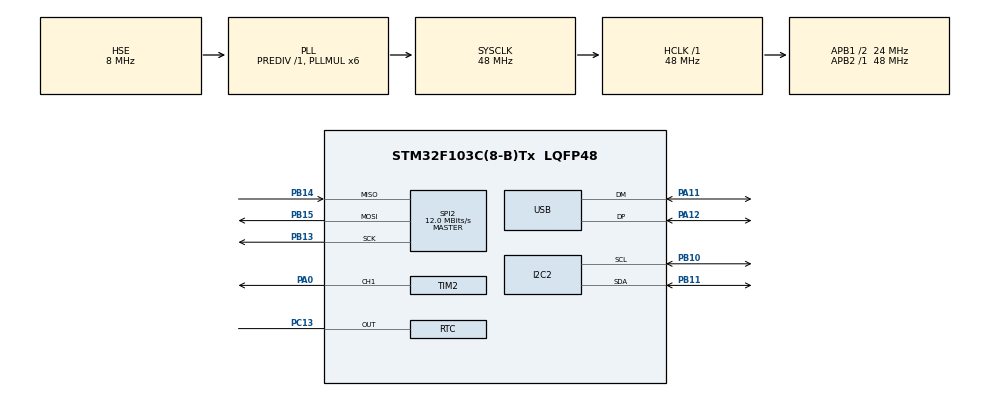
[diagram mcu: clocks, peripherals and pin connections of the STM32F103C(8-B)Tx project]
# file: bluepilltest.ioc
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Mcu.Family=STM32F1
Mcu.Name=STM32F103C(8-B)Tx
Mcu.Package=LQFP48
NVIC.PriorityGroup=NVIC_PRIORITYGROUP_4
NVIC.USB_LP_CAN1_RX0_IRQn=true\:0\:0\:false\:false\:true\:false\:true\:true
PA0-WKUP.Signal=S_TIM2_CH1_ETR
PA11.Mode=Device
PA11.Signal=USB_DM
PA12.Mode=Device
PA12.Signal=USB_DP
PB10.Mode=I2C
PB10.Signal=I2C2_SCL
PB11.Mode=I2C
PB11.Signal=I2C2_SDA
PB13.Mode=Full_Duplex_Master
PB13.Signal=SPI2_SCK
PB14.Mode=Full_Duplex_Master
PB14.Signal=SPI2_MISO
PB15.Mode=Full_Duplex_Master
PB15.Signal=SPI2_MOSI
PC13-TAMPER-RTC.Mode=RTC OUT
PC13-TAMPER-RTC.Signal=RTC_OUT
PD0-OSC_IN.Mode=HSE-External-Oscillator
PD0-OSC_IN.Signal=RCC_OSC_IN
PD1-OSC_OUT.Mode=HSE-External-Oscillator
PD1-OSC_OUT.Signal=RCC_OSC_OUT
ProjectManager.HeapSize=0x200
ProjectManager.StackSize=0x400
ProjectManager.TargetToolchain=Makefile
RCC.AHBFreq_Value=48000000
RCC.APB1CLKDivider=RCC_HCLK_DIV2
RCC.APB1Freq_Value=24000000
RCC.APB1TimFreq_Value=48000000
RCC.APB2Freq_Value=48000000
RCC.APB2TimFreq_Value=48000000
RCC.HCLKFreq_Value=48000000
RCC.PLLMUL=RCC_PLL_MUL6
RCC.SYSCLKFreq_VALUE=48000000
RCC.SYSCLKSource=RCC_SYSCLKSOURCE_PLLCLK
RCC.USBFreq_Value=48000000
SH.S_TIM2_CH1_ETR.0=TIM2_CH1,PWM Generation1 CH1
SPI2.CalculateBaudRate=12.0 MBits/s
SPI2.Direction=SPI_DIRECTION_2LINES
SPI2.Mode=SPI_MODE_MASTER
SPI2.VirtualType=VM_MASTER
TIM2.Channel-PWM\ Generation1\ CH1=TIM_CHANNEL_1
USB_DEVICE.CLASS_NAME_FS=CDC
USB_DEVICE.VirtualMode=Cdc
USB_DEVICE.VirtualModeFS=Cdc_FS
VP_FATFS_VS_Generic.Mode=User_defined
VP_RTC_VS_RTC_Activate.Mode=RTC_Enabled
VP_RTC_VS_RTC_Calendar.Mode=RTC_Calendar
VP_SYS_VS_ND.Mode=No_Debug
VP_TIM2_VS_ClockSourceINT.Mode=Internal
VP_USB_DEVICE_VS_USB_DEVICE_CDC_FS.Mode=CDC_FS
board=custom

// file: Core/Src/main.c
/* USER CODE BEGIN Header */
/**
 ******************************************************************************
 * @file           : main.c
 * @brief          : Main program body
 ******************************************************************************
 * @attention
 *
 * Copyright (c) 2023 STMicroelectronics.
 * All rights reserved.
 *
 * This software is licensed under terms that can be found in the LICENSE file
 * in the root directory of this software component.
 * If no LICENSE file comes with this software, it is provided AS-IS.
 *
 ******************************************************************************
 */
/* USER CODE END Header */
#include "main.h"
#include "fatfs.h"
#include "usb_device.h"
#include "tm_stm32_usb_device.h"
#include "tm_stm32_usb_device_cdc.h"
/* USER CODE BEGIN Includes */
#include <stdbool.h>
/* USER CODE END Includes */

I2C_HandleTypeDef hi2c2;

RTC_HandleTypeDef hrtc;

SPI_HandleTypeDef hspi2;

TIM_HandleTypeDef htim2;

/* USER CODE BEGIN PV */
uint8_t const CMD8 = 0X14;
uint8_t rxBuffer;
/* USER CODE END PV */

void SystemClock_Config(void);
static void MX_GPIO_Init(void);
static void MX_RTC_Init(void);
static void MX_TIM2_Init(void);
static void MX_SPI2_Init(void);
static void MX_I2C2_Init(void);
/* USER CODE BEGIN PFP */
void SendCmdToCard();
/* USER CODE END PFP */

/* USER CODE BEGIN 0 */
void SendCmdToCard(){

  HAL_SPI_Transmit(&hspi2,CMD8,sizeof(CMD8),HAL_MAX_DELAY);

  HAL_SPI_Receive(&hspi2, rxBuffer, sizeof(rxBuffer), HAL_MAX_DELAY);
}
/* USER CODE END 0 */

int main(void)
{

  /* MCU Configuration--------------------------------------------------------*/

  /* Reset of all peripherals, Initializes the Flash interface and the Systick. */
  HAL_Init();

  /* Configure the system clock */
  SystemClock_Config();

  /* Initialize all configured peripherals */
  MX_GPIO_Init();
  MX_RTC_Init();
  MX_TIM2_Init();
  MX_SPI2_Init();
  MX_USB_DEVICE_Init();
  MX_FATFS_Init();
  MX_I2C2_Init();

  /* Infinite loop */
   while (1)
  {

  }
}

void SystemClock_Config(void)
{
  RCC_OscInitTypeDef RCC_OscInitStruct = {0};
  RCC_ClkInitTypeDef RCC_ClkInitStruct = {0};
  RCC_PeriphCLKInitTypeDef PeriphClkInit = {0};

  /** Initializes the RCC Oscillators according to the specified parameters
  * in the RCC_OscInitTypeDef structure.
  */
  RCC_OscInitStruct.OscillatorType = RCC_OSCILLATORTYPE_LSI|RCC_OSCILLATORTYPE_HSE;
  RCC_OscInitStruct.HSEState = RCC_HSE_ON;
  RCC_OscInitStruct.HSEPredivValue = RCC_HSE_PREDIV_DIV1;
  RCC_OscInitStruct.HSIState = RCC_HSI_ON;
  RCC_OscInitStruct.LSIState = RCC_LSI_ON;
  RCC_OscInitStruct.PLL.PLLState = RCC_PLL_ON;
  RCC_OscInitStruct.PLL.PLLSource = RCC_PLLSOURCE_HSE;
  RCC_OscInitStruct.PLL.PLLMUL = RCC_PLL_MUL6;
  if (HAL_RCC_OscConfig(&RCC_OscInitStruct) != HAL_OK)
  {
    Error_Handler();
  }

  /** Initializes the CPU, AHB and APB buses clocks
  */
  RCC_ClkInitStruct.ClockType = RCC_CLOCKTYPE_HCLK|RCC_CLOCKTYPE_SYSCLK
                              |RCC_CLOCKTYPE_PCLK1|RCC_CLOCKTYPE_PCLK2;
  RCC_ClkInitStruct.SYSCLKSource = RCC_SYSCLKSOURCE_PLLCLK;
  RCC_ClkInitStruct.AHBCLKDivider = RCC_SYSCLK_DIV1;
  RCC_ClkInitStruct.APB1CLKDivider = RCC_HCLK_DIV2;
  RCC_ClkInitStruct.APB2CLKDivider = RCC_HCLK_DIV1;

  if (HAL_RCC_ClockConfig(&RCC_ClkInitStruct, FLASH_LATENCY_1) != HAL_OK)
  {
    Error_Handler();
  }
  PeriphClkInit.PeriphClockSelection = RCC_PERIPHCLK_RTC|RCC_PERIPHCLK_USB;
  PeriphClkInit.RTCClockSelection = RCC_RTCCLKSOURCE_LSI;
  PeriphClkInit.UsbClockSelection = RCC_USBCLKSOURCE_PLL;
  if (HAL_RCCEx_PeriphCLKConfig(&PeriphClkInit) != HAL_OK)
  {
    Error_Handler();
  }
}

static void MX_I2C2_Init(void)
{

  hi2c2.Instance = I2C2;
  hi2c2.Init.ClockSpeed = 100000;
  hi2c2.Init.DutyCycle = I2C_DUTYCYCLE_2;
  hi2c2.Init.OwnAddress1 = 0;
  hi2c2.Init.AddressingMode = I2C_ADDRESSINGMODE_7BIT;
  hi2c2.Init.DualAddressMode = I2C_DUALADDRESS_DISABLE;
  hi2c2.Init.OwnAddress2 = 0;
  hi2c2.Init.GeneralCallMode = I2C_GENERALCALL_DISABLE;
  hi2c2.Init.NoStretchMode = I2C_NOSTRETCH_DISABLE;
  if (HAL_I2C_Init(&hi2c2) != HAL_OK)
  {
    Error_Handler();
  }

}

static void MX_RTC_Init(void)
{

  RTC_TimeTypeDef sTime = {0};
  RTC_DateTypeDef DateToUpdate = {0};
  RTC_AlarmTypeDef sAlarm = {0};

  /** Initialize RTC Only
  */
  hrtc.Instance = RTC;
  hrtc.Init.AsynchPrediv = RTC_AUTO_1_SECOND;
  hrtc.Init.OutPut = RTC_OUTPUTSOURCE_ALARM;
  if (HAL_RTC_Init(&hrtc) != HAL_OK)
  {
    Error_Handler();
  }

  /** Initialize RTC and set the Time and Date
  */
  sTime.Hours = 0x0;
  sTime.Minutes = 0x0;
  sTime.Seconds = 0x0;

  if (HAL_RTC_SetTime(&hrtc, &sTime, RTC_FORMAT_BCD) != HAL_OK)
  {
    Error_Handler();
  }
  DateToUpdate.WeekDay = RTC_WEEKDAY_MONDAY;
  DateToUpdate.Month = RTC_MONTH_JANUARY;
  DateToUpdate.Date = 0x1;
  DateToUpdate.Year = 0x0;

  if (HAL_RTC_SetDate(&hrtc, &DateToUpdate, RTC_FORMAT_BCD) != HAL_OK)
  {
    Error_Handler();
  }

  /** Enable the Alarm A
  */
  sAlarm.AlarmTime.Hours = 0x0;
  sAlarm.AlarmTime.Minutes = 0x0;
  sAlarm.AlarmTime.Seconds = 0x0;
  sAlarm.Alarm = RTC_ALARM_A;
  if (HAL_RTC_SetAlarm(&hrtc, &sAlarm, RTC_FORMAT_BCD) != HAL_OK)
  {
    Error_Handler();
  }

}

static void MX_SPI2_Init(void)
{

  /* SPI2 parameter configuration*/
  hspi2.Instance = SPI2;
  hspi2.Init.Mode = SPI_MODE_MASTER;
  hspi2.Init.Direction = SPI_DIRECTION_2LINES;
  hspi2.Init.DataSize = SPI_DATASIZE_8BIT;
  hspi2.Init.CLKPolarity = SPI_POLARITY_LOW;
  hspi2.Init.CLKPhase = SPI_PHASE_1EDGE;
  hspi2.Init.NSS = SPI_NSS_SOFT;
  hspi2.Init.BaudRatePrescaler = SPI_BAUDRATEPRESCALER_2;
  hspi2.Init.FirstBit = SPI_FIRSTBIT_MSB;
  hspi2.Init.TIMode = SPI_TIMODE_DISABLE;
  hspi2.Init.CRCCalculation = SPI_CRCCALCULATION_DISABLE;
  hspi2.Init.CRCPolynomial = 10;
  if (HAL_SPI_Init(&hspi2) != HAL_OK)
  {
    Error_Handler();
  }

}

static void MX_TIM2_Init(void)
{

  TIM_ClockConfigTypeDef sClockSourceConfig = {0};
  TIM_MasterConfigTypeDef sMasterConfig = {0};
  TIM_OC_InitTypeDef sConfigOC = {0};

  htim2.Instance = TIM2;
  htim2.Init.Prescaler = 0;
  htim2.Init.CounterMode = TIM_COUNTERMODE_UP;
  htim2.Init.Period = 65535;
  htim2.Init.ClockDivision = TIM_CLOCKDIVISION_DIV1;
  htim2.Init.AutoReloadPreload = TIM_AUTORELOAD_PRELOAD_DISABLE;
  if (HAL_TIM_Base_Init(&htim2) != HAL_OK)
  {
    Error_Handler();
  }
  sClockSourceConfig.ClockSource = TIM_CLOCKSOURCE_INTERNAL;
  if (HAL_TIM_ConfigClockSource(&htim2, &sClockSourceConfig) != HAL_OK)
  {
    Error_Handler();
  }
  if (HAL_TIM_PWM_Init(&htim2) != HAL_OK)
  {
    Error_Handler();
  }
  sMasterConfig.MasterOutputTrigger = TIM_TRGO_RESET;
  sMasterConfig.MasterSlaveMode = TIM_MASTERSLAVEMODE_DISABLE;
  if (HAL_TIMEx_MasterConfigSynchronization(&htim2, &sMasterConfig) != HAL_OK)
  {
    Error_Handler();
  }
  sConfigOC.OCMode = TIM_OCMODE_PWM1;
  sConfigOC.Pulse = 0;
  sConfigOC.OCPolarity = TIM_OCPOLARITY_HIGH;
  sConfigOC.OCFastMode = TIM_OCFAST_DISABLE;
  if (HAL_TIM_PWM_ConfigChannel(&htim2, &sConfigOC, TIM_CHANNEL_1) != HAL_OK)
  {
    Error_Handler();
  }
  HAL_TIM_MspPostInit(&htim2);

}

static void MX_GPIO_Init(void)
{

  /* GPIO Ports Clock Enable */
  __HAL_RCC_GPIOC_CLK_ENABLE();
  __HAL_RCC_GPIOD_CLK_ENABLE();
  __HAL_RCC_GPIOA_CLK_ENABLE();
  __HAL_RCC_GPIOB_CLK_ENABLE();

}

void Error_Handler(void)
{
  __disable_irq();
  while (1)
  {
  }
}
